# EFR32BG13P632F512GM48 register map
File version: 5.5.0
Registers are 32-bit, read-write, reset 0x0 unless marked. A register's access mark holds for its fields unless they carry their own. Offsets are from the block's base; [hi:lo] are bit positions; {n}, {i} and the like mark numbered series; 'fields as' and 'values as' point back to an identical list.

## FPUEH
Base 0x400E1000
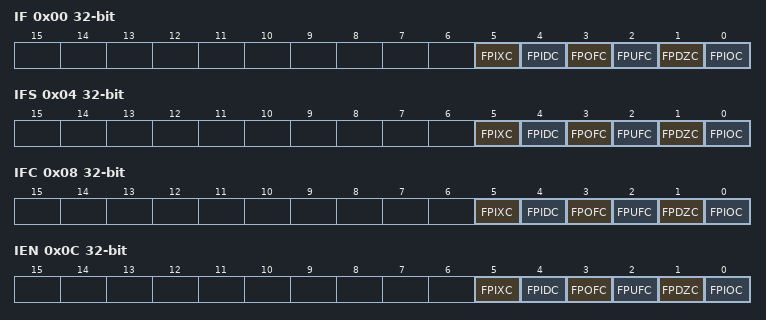
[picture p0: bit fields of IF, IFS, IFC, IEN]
0x00 IF ro — Interrupt Flag Register
  [5] FPIXC — FPU inexact exception
  [4] FPIDC — FPU input denormal exception
  [3] FPOFC — FPU overflow exception
  [2] FPUFC — FPU underflow exception
  [1] FPDZC — FPU divide-by-zero exception
  [0] FPIOC — FPU invalid operation
0x04 IFS wo — Interrupt Flag Set Register
  [5] FPIXC — Set FPIXC Interrupt Flag
  [4] FPIDC — Set FPIDC Interrupt Flag
  [3] FPOFC — Set FPOFC Interrupt Flag
  [2] FPUFC — Set FPUFC Interrupt Flag
  [1] FPDZC — Set FPDZC Interrupt Flag
  [0] FPIOC — Set FPIOC Interrupt Flag
0x08 IFC wo — Interrupt Flag Clear Register
  [5] FPIXC — Clear FPIXC Interrupt Flag
  [4] FPIDC — Clear FPIDC Interrupt Flag
  [3] FPOFC — Clear FPOFC Interrupt Flag
  [2] FPUFC — Clear FPUFC Interrupt Flag
  [1] FPDZC — Clear FPDZC Interrupt Flag
  [0] FPIOC — Clear FPIOC Interrupt Flag
0x0C IEN — Interrupt Enable Register
  [5] FPIXC — FPIXC Interrupt Enable
  [4] FPIDC — FPIDC Interrupt Enable
  [3] FPOFC — FPOFC Interrupt Enable
  [2] FPUFC — FPUFC Interrupt Enable
  [1] FPDZC — FPDZC Interrupt Enable
  [0] FPIOC — FPIOC Interrupt Enable

## GPCRC
Base 0x4001C000
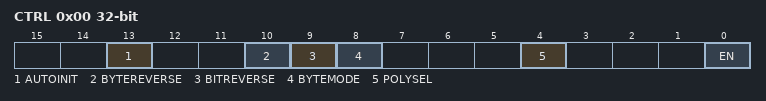
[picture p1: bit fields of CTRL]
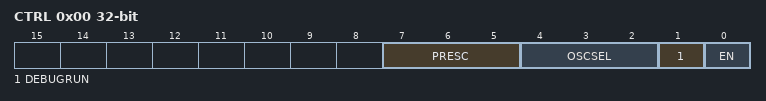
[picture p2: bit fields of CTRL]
0x00 CTRL — Control Register
  [13] AUTOINIT — Auto Init Enable
  [10] BYTEREVERSE — Byte Reverse Mode
  [9] BITREVERSE — Byte-level Bit Reverse Enable
  [8] BYTEMODE — Byte Mode Enable
  [4] POLYSEL — Polynomial Select
  [0] EN — CRC Functionality Enable
0x04 CMD wo — Command Register
  [0] INIT — Initialization Enable
0x08 INIT — CRC Init Value
  [31:0] INIT — CRC Initialization Value
0x0C POLY — CRC Polynomial Value
  [15:0] POLY
0x10 INPUTDATA — Input 32-bit Data Register
  [31:0] INPUTDATA — Input Data for 32-bit
0x14 INPUTDATAHWORD — Input 16-bit Data Register
  [15:0] INPUTDATAHWORD — Input Data for 16-bit
0x18 INPUTDATABYTE — Input 8-bit Data Register
  [7:0] INPUTDATABYTE — Input Data for 8-bit
0x1C DATA ro — CRC Data Register
0x20 DATAREV ro — CRC Data Reverse Register
  [31:0] DATAREV — Data Reverse Value
0x24 DATABYTEREV ro — CRC Data Byte Reverse Register
  [31:0] DATABYTEREV — Data Byte Reverse Value

## CRYOTIMER
Base 0x4001E000
0x00 CTRL — Control Register
  [7:5] PRESC — Prescaler Setting
    0=DIV1 (LF Oscillator frequency undivided); 1=DIV2 (LF Oscillator frequency divided by 2); 2=DIV4 (LF Oscillator frequency divided by 4); 3=DIV8 (LF Oscillator frequency divided by 8); 4=DIV16 (LF Oscillator frequency divided by 16); 5=DIV32 (LF Oscillator frequency divided by 32); 6=DIV64 (LF Oscillator frequency divided by 64); 7=DIV128 (LF Oscillator frequency divided by 128)
  [4:2] OSCSEL — Select Low Frequency Oscillator
    0=DISABLED (Output is driven low); 1=LFRCO (Select Low Frequency RC Oscillator); 2=LFXO (Select Low Frequency Crystal Oscillator); 3=ULFRCO (Select Ultra Low Frequency RC Oscillator)
  [1] DEBUGRUN — Debug Mode Run Enable
  [0] EN — Enable CRYOTIMER
0x04 PERIODSEL reset 0x20 — Interrupt Duration
  [5:0] PERIODSEL — Interrupts/Wakeup Events Period Setting
0x08 CNT ro — Counter Value
0x0C EM4WUEN — Wake Up Enable
  [0] EM4WU — EM4 Wake-up Enable
0x10 IF ro — Interrupt Flag Register
  [0] PERIOD — Wakeup Event/Interrupt
0x14 IFS wo — Interrupt Flag Set Register
  [0] PERIOD — Set PERIOD Interrupt Flag
0x18 IFC wo — Interrupt Flag Clear Register
  [0] PERIOD — Clear PERIOD Interrupt Flag
0x1C IEN — Interrupt Enable Register
  [0] PERIOD — PERIOD Interrupt Enable

## WDOG0
Base 0x40052000
Same registers: WDOG1 0x40052400
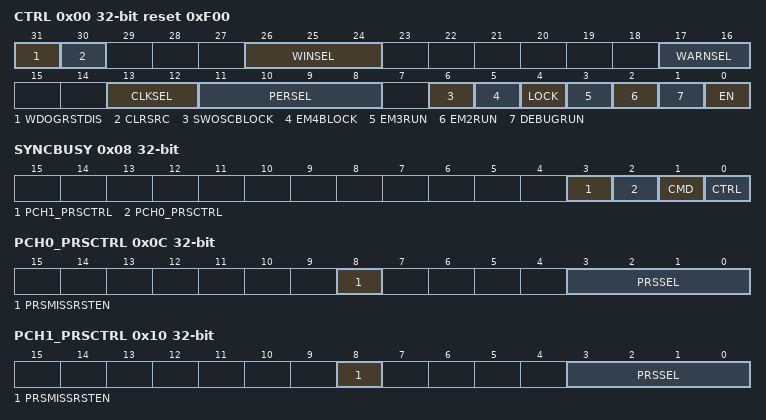
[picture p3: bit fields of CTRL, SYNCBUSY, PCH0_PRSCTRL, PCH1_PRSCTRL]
0x00 CTRL reset 0xF00 — Control Register
  [31] WDOGRSTDIS — Watchdog Reset Disable
  [30] CLRSRC — Watchdog Clear Source
  [26:24] WINSEL — Watchdog Illegal Window Select
  [17:16] WARNSEL — Watchdog Timeout Period Select
  [13:12] CLKSEL — Watchdog Clock Select
    0=ULFRCO; 1=LFRCO; 2=LFXO; 3=HFCORECLK
  [11:8] PERSEL — Watchdog Timeout Period Select
  [6] SWOSCBLOCK — Software Oscillator Disable Block
  [5] EM4BLOCK — Energy Mode 4 Block
  [4] LOCK — Configuration Lock
  [3] EM3RUN — Energy Mode 3 Run Enable
  [2] EM2RUN — Energy Mode 2 Run Enable
  [1] DEBUGRUN — Debug Mode Run Enable
  [0] EN — Watchdog Timer Enable
0x04 CMD wo — Command Register
  [0] CLEAR — Watchdog Timer Clear
0x08 SYNCBUSY ro — Synchronization Busy Register
  [3] PCH1_PRSCTRL — PCH1_PRSCTRL Register Busy
  [2] PCH0_PRSCTRL — PCH0_PRSCTRL Register Busy
  [1] CMD — CMD Register Busy
  [0] CTRL — CTRL Register Busy
0x0C PCH0_PRSCTRL — PRS Control Register
  [8] PRSMISSRSTEN — PRS Missing Event Will Trigger a Watchdog Reset
  [3:0] PRSSEL — PRS Channel PRS Select
    {v}=PRSCH{v} (PRS Channel {v} selected as input) (v=0..11)
0x10 PCH1_PRSCTRL — PRS Control Register
  fields as PCH0_PRSCTRL
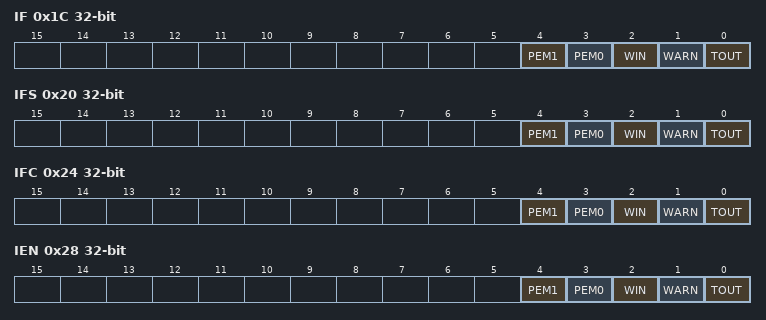
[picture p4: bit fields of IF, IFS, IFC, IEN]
0x1C IF ro — Watchdog Interrupt Flags
  [4] PEM1 — PRS Channel One Event Missing Interrupt Flag
  [3] PEM0 — PRS Channel Zero Event Missing Interrupt Flag
  [2] WIN — WDOG Window Interrupt Flag
  [1] WARN — WDOG Warning Timeout Interrupt Flag
  [0] TOUT — WDOG Timeout Interrupt Flag
0x20 IFS wo — Interrupt Flag Set Register
  [4] PEM1 — Set PEM1 Interrupt Flag
  [3] PEM0 — Set PEM0 Interrupt Flag
  [2] WIN — Set WIN Interrupt Flag
  [1] WARN — Set WARN Interrupt Flag
  [0] TOUT — Set TOUT Interrupt Flag
0x24 IFC wo — Interrupt Flag Clear Register
  [4] PEM1 — Clear PEM1 Interrupt Flag
  [3] PEM0 — Clear PEM0 Interrupt Flag
  [2] WIN — Clear WIN Interrupt Flag
  [1] WARN — Clear WARN Interrupt Flag
  [0] TOUT — Clear TOUT Interrupt Flag
0x28 IEN — Interrupt Enable Register
  [4] PEM1 — PEM1 Interrupt Enable
  [3] PEM0 — PEM0 Interrupt Enable
  [2] WIN — WIN Interrupt Enable
  [1] WARN — WARN Interrupt Enable
  [0] TOUT — TOUT Interrupt Enable
